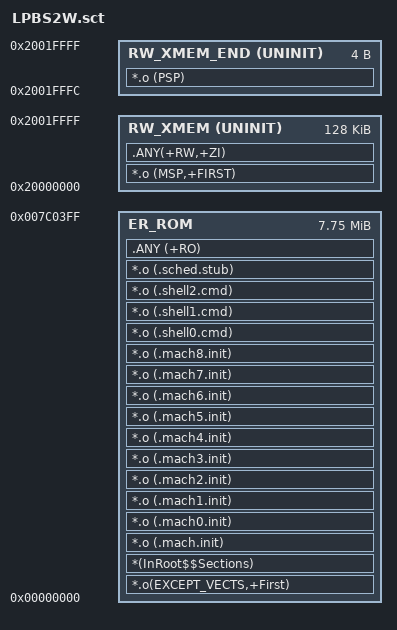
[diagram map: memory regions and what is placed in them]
; *************************************************************
; *** Scatter-Loading Description File generated by uVision ***
; *************************************************************
LR_FLASH 0x00000000 0x00800000  {;load region size_region
	ER_ROM 0x00000000 0x00800000 - 255 * 1024  {;execution address = load address
		*.o(EXCEPT_VECTS,+First)
		*(InRoot$$Sections)
		*.o (.mach.init)
        *.o (.mach0.init)
        *.o (.mach1.init)
        *.o (.mach2.init)
        *.o (.mach3.init)
        *.o (.mach4.init)
        *.o (.mach5.init)
        *.o (.mach6.init)   
        *.o (.mach7.init)
        *.o (.mach8.init)
        *.o (.shell0.cmd)
        *.o (.shell1.cmd)
        *.o (.shell2.cmd)
        *.o (.sched.stub)
		.ANY (+RO)
	}
	
    RW_XMEM 0x20000000 UNINIT 0x20000  {;64+32+32KB XVPMEM
		*.o (MSP,+FIRST)
		.ANY(+RW,+ZI)
	}

    RW_XMEM_END 0x20020000 - 4 UNINIT 4{
		*.o (PSP)
	}
}

